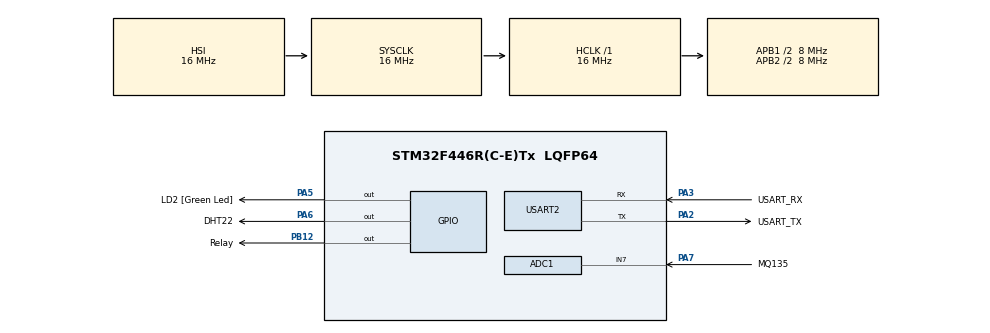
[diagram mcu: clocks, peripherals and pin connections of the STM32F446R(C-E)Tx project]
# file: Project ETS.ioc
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ADC1.Channel-0\#ChannelRegularConversion=ADC_CHANNEL_7
ADC1.NbrOfConversionFlag=1
ADC1.Rank-0\#ChannelRegularConversion=1
ADC1.SamplingTime-0\#ChannelRegularConversion=ADC_SAMPLETIME_3CYCLES
ADC1.master=1
Mcu.Family=STM32F4
Mcu.Name=STM32F446R(C-E)Tx
Mcu.Package=LQFP64
NVIC.PriorityGroup=NVIC_PRIORITYGROUP_0
PA13.GPIO_Label=TMS
PA13.Mode=Serial_Wire
PA13.Signal=SYS_JTMS-SWDIO
PA14.GPIO_Label=TCK
PA14.Mode=Serial_Wire
PA14.Signal=SYS_JTCK-SWCLK
PA2.GPIO_Label=USART_TX
PA2.Mode=Asynchronous
PA2.Signal=USART2_TX
PA3.GPIO_Label=USART_RX
PA3.Mode=Asynchronous
PA3.Signal=USART2_RX
PA5.GPIO_Label=LD2 [Green Led]
PA5.Signal=GPIO_Output
PA6.GPIO_Label=DHT22
PA6.Signal=GPIO_Output
PA7.GPIO_Label=MQ135
PA7.Signal=ADCx_IN7
PB12.GPIO_Label=Relay
PB12.Signal=GPIO_Output
PB3.GPIO_Label=SWO
PB3.Signal=SYS_JTDO-SWO
PC14-OSC32_IN.Mode=LSE-External-Oscillator
PC14-OSC32_IN.Signal=RCC_OSC32_IN
PC15-OSC32_OUT.Mode=LSE-External-Oscillator
PC15-OSC32_OUT.Signal=RCC_OSC32_OUT
PH0-OSC_IN.Mode=HSE-External-Oscillator
PH0-OSC_IN.Signal=RCC_OSC_IN
PH1-OSC_OUT.Mode=HSE-External-Oscillator
PH1-OSC_OUT.Signal=RCC_OSC_OUT
ProjectManager.HeapSize=0x200
ProjectManager.StackSize=0x400
ProjectManager.TargetToolchain=MDK-ARM V5.32
RCC.48MHZClocksFreq_Value=84000000
RCC.AHBFreq_Value=16000000
RCC.APB1CLKDivider=RCC_HCLK_DIV2
RCC.APB1Freq_Value=8000000
RCC.APB1TimFreq_Value=16000000
RCC.APB2CLKDivider=RCC_HCLK_DIV2
RCC.APB2Freq_Value=8000000
RCC.APB2TimFreq_Value=16000000
RCC.CortexFreq_Value=16000000
RCC.FLatency-AdvancedSettings=FLASH_LATENCY_0
RCC.HCLKFreq_Value=16000000
RCC.HSE_VALUE=8000000
RCC.HSI_VALUE=16000000
RCC.PLLM=4
RCC.PLLN=80
RCC.SYSCLKFreq_VALUE=16000000
RCC.USBFreq_Value=160000000
RCC.VCOOutputFreq_Value=320000000
SH.ADCx_IN7.0=ADC1_IN7,IN7
TIM1.Prescaler=80-1
USART2.VirtualMode=VM_ASYNC
VP_TIM1_VS_ClockSourceINT.Mode=Internal
board=NUCLEO-F446RE

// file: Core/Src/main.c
/* USER CODE BEGIN Header */
/**
  ******************************************************************************
  * @file           : main.c
  * @brief          : Main program body
  ******************************************************************************
  * @attention
  *
  * Copyright (c) 2025 STMicroelectronics.
  * All rights reserved.
  *
  * This software is licensed under terms that can be found in the LICENSE file
  * in the root directory of this software component.
  * If no LICENSE file comes with this software, it is provided AS-IS.
  *
  ******************************************************************************
  */
/* USER CODE END Header */
#include "main.h"
#include "relay.h"
#include "dht22.h"
#include "mq135.h"

ADC_HandleTypeDef hadc1;

TIM_HandleTypeDef htim1;

UART_HandleTypeDef huart2;

void SystemClock_Config(void);
static void MX_GPIO_Init(void);
static void MX_ADC1_Init(void);
static void MX_TIM1_Init(void);
static void MX_USART2_UART_Init(void);

int main(void)
{

  /* USER CODE BEGIN 1 */
	float temperature = 0.0f;
	float humidity = 0.0f;
  /* USER CODE END 1 */

  /* MCU Configuration--------------------------------------------------------*/

  /* Reset of all peripherals, Initializes the Flash interface and the Systick. */
  HAL_Init();

  /* USER CODE BEGIN Init */
	DHT22_Init(GPIOA, GPIO_PIN_2);
	Relay_Init(GPIOB, GPIO_PIN_12);
  /* USER CODE END Init */

  /* Configure the system clock */
  SystemClock_Config();

  /* Initialize all configured peripherals */
  MX_GPIO_Init();
  MX_ADC1_Init();
  MX_TIM1_Init();
  MX_USART2_UART_Init();

  /* Infinite loop */
  while (1)
  {
		bool concentration = MQ135_Read(&hadc1);
		bool temperature = DHT22_Read(GPIOA, GPIO_PIN_6);
		if(concentration || temperature) {
			Relay_On(GPIOB, GPIO_PIN_12);
			HAL_Delay(180000); // Aktif 3 menit
			Relay_Off(GPIOB, GPIO_PIN_12);
			/* Delay 2 detik */
			HAL_Delay(2000);
		}else {
			Relay_Off(GPIOB, GPIO_PIN_12);
		}
		HAL_Delay(1000);

  }
}

void SystemClock_Config(void)
{
  RCC_OscInitTypeDef RCC_OscInitStruct = {0};
  RCC_ClkInitTypeDef RCC_ClkInitStruct = {0};

  /** Configure the main internal regulator output voltage
  */
  __HAL_RCC_PWR_CLK_ENABLE();
  __HAL_PWR_VOLTAGESCALING_CONFIG(PWR_REGULATOR_VOLTAGE_SCALE3);

  /** Initializes the RCC Oscillators according to the specified parameters
  * in the RCC_OscInitTypeDef structure.
  */
  RCC_OscInitStruct.OscillatorType = RCC_OSCILLATORTYPE_HSI;
  RCC_OscInitStruct.HSIState = RCC_HSI_ON;
  RCC_OscInitStruct.HSICalibrationValue = RCC_HSICALIBRATION_DEFAULT;
  RCC_OscInitStruct.PLL.PLLState = RCC_PLL_NONE;
  if (HAL_RCC_OscConfig(&RCC_OscInitStruct) != HAL_OK)
  {
    Error_Handler();
  }

  /** Initializes the CPU, AHB and APB buses clocks
  */
  RCC_ClkInitStruct.ClockType = RCC_CLOCKTYPE_HCLK|RCC_CLOCKTYPE_SYSCLK
                              |RCC_CLOCKTYPE_PCLK1|RCC_CLOCKTYPE_PCLK2;
  RCC_ClkInitStruct.SYSCLKSource = RCC_SYSCLKSOURCE_HSI;
  RCC_ClkInitStruct.AHBCLKDivider = RCC_SYSCLK_DIV1;
  RCC_ClkInitStruct.APB1CLKDivider = RCC_HCLK_DIV2;
  RCC_ClkInitStruct.APB2CLKDivider = RCC_HCLK_DIV2;

  if (HAL_RCC_ClockConfig(&RCC_ClkInitStruct, FLASH_LATENCY_0) != HAL_OK)
  {
    Error_Handler();
  }
}

static void MX_ADC1_Init(void)
{

  ADC_ChannelConfTypeDef sConfig = {0};

  /** Configure the global features of the ADC (Clock, Resolution, Data Alignment and number of conversion)
  */
  hadc1.Instance = ADC1;
  hadc1.Init.ClockPrescaler = ADC_CLOCK_SYNC_PCLK_DIV2;
  hadc1.Init.Resolution = ADC_RESOLUTION_12B;
  hadc1.Init.ScanConvMode = DISABLE;
  hadc1.Init.ContinuousConvMode = DISABLE;
  hadc1.Init.DiscontinuousConvMode = DISABLE;
  hadc1.Init.ExternalTrigConvEdge = ADC_EXTERNALTRIGCONVEDGE_NONE;
  hadc1.Init.ExternalTrigConv = ADC_SOFTWARE_START;
  hadc1.Init.DataAlign = ADC_DATAALIGN_RIGHT;
  hadc1.Init.NbrOfConversion = 1;
  hadc1.Init.DMAContinuousRequests = DISABLE;
  hadc1.Init.EOCSelection = ADC_EOC_SINGLE_CONV;
  if (HAL_ADC_Init(&hadc1) != HAL_OK)
  {
    Error_Handler();
  }

  /** Configure for the selected ADC regular channel its corresponding rank in the sequencer and its sample time.
  */
  sConfig.Channel = ADC_CHANNEL_7;
  sConfig.Rank = 1;
  sConfig.SamplingTime = ADC_SAMPLETIME_3CYCLES;
  if (HAL_ADC_ConfigChannel(&hadc1, &sConfig) != HAL_OK)
  {
    Error_Handler();
  }

}

static void MX_TIM1_Init(void)
{

  TIM_ClockConfigTypeDef sClockSourceConfig = {0};
  TIM_MasterConfigTypeDef sMasterConfig = {0};

  htim1.Instance = TIM1;
  htim1.Init.Prescaler = 80-1;
  htim1.Init.CounterMode = TIM_COUNTERMODE_UP;
  htim1.Init.Period = 65535;
  htim1.Init.ClockDivision = TIM_CLOCKDIVISION_DIV1;
  htim1.Init.RepetitionCounter = 0;
  htim1.Init.AutoReloadPreload = TIM_AUTORELOAD_PRELOAD_DISABLE;
  if (HAL_TIM_Base_Init(&htim1) != HAL_OK)
  {
    Error_Handler();
  }
  sClockSourceConfig.ClockSource = TIM_CLOCKSOURCE_INTERNAL;
  if (HAL_TIM_ConfigClockSource(&htim1, &sClockSourceConfig) != HAL_OK)
  {
    Error_Handler();
  }
  sMasterConfig.MasterOutputTrigger = TIM_TRGO_RESET;
  sMasterConfig.MasterSlaveMode = TIM_MASTERSLAVEMODE_DISABLE;
  if (HAL_TIMEx_MasterConfigSynchronization(&htim1, &sMasterConfig) != HAL_OK)
  {
    Error_Handler();
  }

}

static void MX_USART2_UART_Init(void)
{

  huart2.Instance = USART2;
  huart2.Init.BaudRate = 115200;
  huart2.Init.WordLength = UART_WORDLENGTH_8B;
  huart2.Init.StopBits = UART_STOPBITS_1;
  huart2.Init.Parity = UART_PARITY_NONE;
  huart2.Init.Mode = UART_MODE_TX_RX;
  huart2.Init.HwFlowCtl = UART_HWCONTROL_NONE;
  huart2.Init.OverSampling = UART_OVERSAMPLING_16;
  if (HAL_UART_Init(&huart2) != HAL_OK)
  {
    Error_Handler();
  }

}

static void MX_GPIO_Init(void)
{
  GPIO_InitTypeDef GPIO_InitStruct = {0};

  /* GPIO Ports Clock Enable */
  __HAL_RCC_GPIOC_CLK_ENABLE();
  __HAL_RCC_GPIOH_CLK_ENABLE();
  __HAL_RCC_GPIOA_CLK_ENABLE();
  __HAL_RCC_GPIOB_CLK_ENABLE();

  /*Configure GPIO pin Output Level */
  HAL_GPIO_WritePin(GPIOA, LD2_Pin|DHT22_Pin, GPIO_PIN_RESET);

  /*Configure GPIO pin Output Level */
  HAL_GPIO_WritePin(Relay_GPIO_Port, Relay_Pin, GPIO_PIN_RESET);

  /*Configure GPIO pins : LD2_Pin DHT22_Pin */
  GPIO_InitStruct.Pin = LD2_Pin|DHT22_Pin;
  GPIO_InitStruct.Mode = GPIO_MODE_OUTPUT_PP;
  GPIO_InitStruct.Pull = GPIO_NOPULL;
  GPIO_InitStruct.Speed = GPIO_SPEED_FREQ_LOW;
  HAL_GPIO_Init(GPIOA, &GPIO_InitStruct);

  /*Configure GPIO pin : Relay_Pin */
  GPIO_InitStruct.Pin = Relay_Pin;
  GPIO_InitStruct.Mode = GPIO_MODE_OUTPUT_PP;
  GPIO_InitStruct.Pull = GPIO_NOPULL;
  GPIO_InitStruct.Speed = GPIO_SPEED_FREQ_LOW;
  HAL_GPIO_Init(Relay_GPIO_Port, &GPIO_InitStruct);

}

void Error_Handler(void)
{
}
